# PY32F0xx_DFP register map
Vendor: Puya; Series: PY32F0; File version: 1.0.0
CPU: CM0+ r0p1, little endian, no MPU, no FPU, 4 interrupt priority bits
Registers are 32-bit, read-write, reset 0x0 unless marked. A register's access mark holds for its fields unless they carry their own. Offsets are from the block's base; [hi:lo] are bit positions.

## LPTIM — Low power timer
Base 0x40007C00
0x00 ISR ro — Interrupt and Status Register
  [1] ARRM — Autoreload match
0x04 ICR wo — Interrupt Clear Register
  [1] ARRMCF — Autoreload match Clear Flag
0x08 IER — Interrupt Enable Register
  [1] ARRMIE — Autoreload match Interrupt Enable
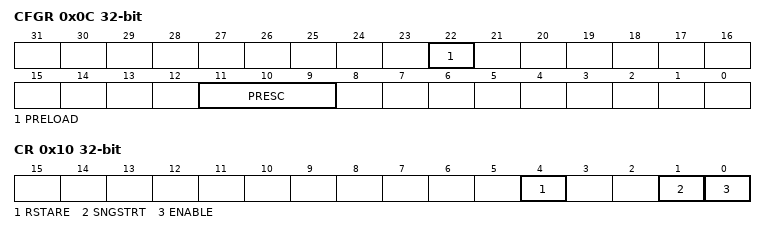
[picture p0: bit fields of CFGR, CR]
0x0C CFGR — Configuration Register
  [22] PRELOAD — Registers update mode
  [11:9] PRESC — Clock prescaler
0x10 CR — Control Register
  [4] RSTARE — Reset after read enable
  [1] SNGSTRT — LPTIM start in single mode
  [0] ENABLE — LPTIM Enable
0x18 ARR reset 0x1 — Autoreload Register
  [15:0] ARR — Auto reload value
0x1C CNT ro — Counter Register
  [15:0] CNT — Counter value

## USART1 — Universal synchronous asynchronous receiver transmitter
Base 0x40013800
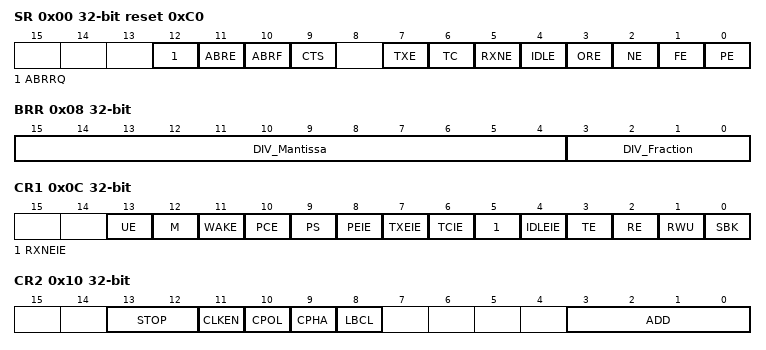
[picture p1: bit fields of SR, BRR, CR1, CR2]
0x00 SR reset 0xC0 — Status register
  [12] ABRRQ wo — Automate baudrate detection requeset
  [11] ABRE ro — Automate baudrate detection error flag
  [10] ABRF ro — Automate baudrate detection flag
  [9] CTS — CTS flag
  [7] TXE ro — Transmit data register empty
  [6] TC — Transmission complete
  [5] RXNE — Read data register not empty
  [4] IDLE ro — IDLE line detected
  [3] ORE ro — Overrun error
  [2] NE ro — Noise error flag
  [1] FE ro — Framing error
  [0] PE ro — Parity error
0x04 DR — Data register
  [8:0] DR — Data value
0x08 BRR — Baud rate register
  [15:4] DIV_Mantissa — mantissa of USARTDIV
  [3:0] DIV_Fraction — fraction of USARTDIV
0x0C CR1 — Control register 1
  [13] UE — USART enable
  [12] M — Word length
  [11] WAKE — Wakeup method
  [10] PCE — Parity control enable
  [9] PS — Parity selection
  [8] PEIE — PE interrupt enable
  [7] TXEIE — TXE interrupt enable
  [6] TCIE — Transmission complete interrupt enable
  [5] RXNEIE — RXNE interrupt enable
  [4] IDLEIE — IDLE interrupt enable
  [3] TE — Transmitter enable
  [2] RE — Receiver enable
  [1] RWU — Receiver wakeup
  [0] SBK — Send break
0x10 CR2 — Control register 2
  [13:12] STOP — STOP bits
  [11] CLKEN — Clock enable
  [10] CPOL — Clock polarity
  [9] CPHA — Clock phase
  [8] LBCL — Last bit clock pulse
  [3:0] ADD — Address of the USART node
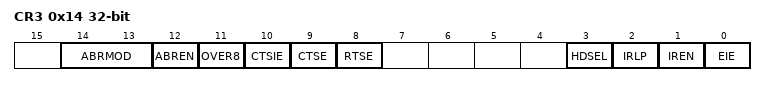
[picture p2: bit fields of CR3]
0x14 CR3 — Control register 3
  [14:13] ABRMOD — Auto baudrate mode
  [12] ABREN — Auto baudrate enable
  [11] OVER8 — Oversampling mode
  [10] CTSIE — CTS interrupt enable
  [9] CTSE — CTS enable
  [8] RTSE — RTS enable
  [3] HDSEL — Half-duplex selection
  [2] IRLP — IrDA low-power
  [1] IREN — IrDA mode enable
  [0] EIE — Error interrupt enable

## IWDG — Independent watchdog
Base 0x40003000
0x00 KR wo — Key register (IWDG_KR)
  [15:0] KEY — Key value
0x04 PR — Prescaler register (IWDG_PR)
  [2:0] PR — Prescaler divider
0x08 RLR reset 0xFFF — Reload register (IWDG_RLR)
  [11:0] RL — Watchdog counter reload value
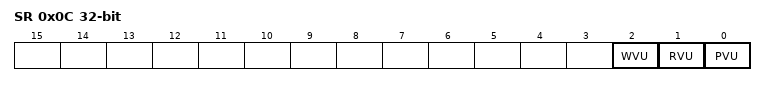
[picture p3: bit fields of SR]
0x0C SR ro — Status register (IWDG_SR)
  [2] WVU — Watchdog counter window value update
  [1] RVU — Watchdog counter reload value update
  [0] PVU — Watchdog prescaler value update
0x10 WINR ro — Window register (IWDG_SR)
  [11:0] WIN — window counter

## TIM16 — General purpose timer
Base 0x40014400
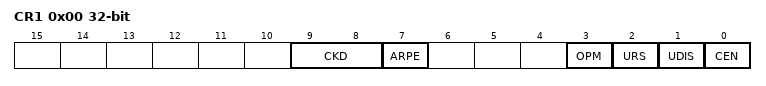
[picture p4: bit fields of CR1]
0x00 CR1 — TIM16 control register1
  [9:8] CKD — Prescaler factor
  [7] ARPE — Auto-reload preload enable
  [3] OPM — One pulse mode
  [2] URS — Update request source
  [1] UDIS — Update disable
  [0] CEN — Counter enable
0x0C DIER — DMA/Interrupt enable register
  [0] UIE — Update interrupt enable
0x10 SR — status register
  [0] UIF — Update interrupt flag
0x14 EGR wo — event generation register
  [0] UG — Update generation
0x24 CNT — counter
  [15:0] CNT — counter value
0x28 PSC — prescaler
  [15:0] PSC — Prescaler value
0x2C ARR — auto-reload register
  [15:0] ARR — Auto-reload value
0x30 RCR — repetition counter register
  [7:0] REP — Repetition counter value
